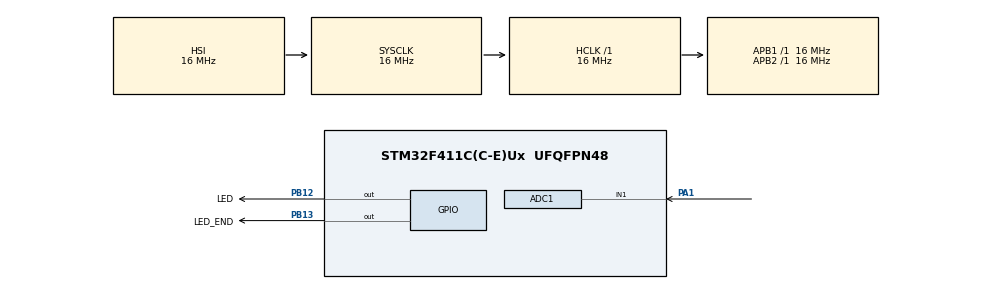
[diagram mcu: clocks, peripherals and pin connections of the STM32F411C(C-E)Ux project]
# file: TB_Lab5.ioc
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ADC1.Channel-2\#ChannelRegularConversion=ADC_CHANNEL_1
ADC1.InjNumberOfConversion=0
ADC1.NbrOfConversionFlag=1
ADC1.Rank-2\#ChannelRegularConversion=1
ADC1.SamplingTime-2\#ChannelRegularConversion=ADC_SAMPLETIME_3CYCLES
ADC1.master=1
Dma.ADC1.0.Direction=DMA_PERIPH_TO_MEMORY
Dma.ADC1.0.FIFOMode=DMA_FIFOMODE_DISABLE
Dma.ADC1.0.Instance=DMA2_Stream0
Dma.ADC1.0.MemDataAlignment=DMA_MDATAALIGN_HALFWORD
Dma.ADC1.0.MemInc=DMA_MINC_ENABLE
Dma.ADC1.0.Mode=DMA_NORMAL
Dma.ADC1.0.PeriphDataAlignment=DMA_PDATAALIGN_HALFWORD
Dma.ADC1.0.PeriphInc=DMA_PINC_DISABLE
Dma.ADC1.0.Priority=DMA_PRIORITY_LOW
Dma.Request0=ADC1
Mcu.Family=STM32F4
Mcu.Name=STM32F411C(C-E)Ux
Mcu.Package=UFQFPN48
NVIC.DMA2_Stream0_IRQn=true\:0\:0\:false\:false\:true\:false\:true\:true
NVIC.PriorityGroup=NVIC_PRIORITYGROUP_4
NVIC.RTC_WKUP_IRQn=true\:0\:0\:false\:false\:true\:true\:true\:true
NVIC.TIM3_IRQn=true\:0\:0\:false\:false\:true\:true\:true\:true
PA0-WKUP.GPIO_Label=WKUP
PA0-WKUP.Mode=SYS_WakeUp0
PA0-WKUP.Signal=SYS_WKUP
PA1.Signal=ADCx_IN1
PB12.GPIO_Label=LED
PB12.Signal=GPIO_Output
PB13.GPIO_Label=LED_END
PB13.Signal=GPIO_Output
ProjectManager.HeapSize=0x200
ProjectManager.StackSize=0x400
ProjectManager.TargetToolchain=STM32CubeIDE
RCC.AHBFreq_Value=16000000
RCC.APB1Freq_Value=16000000
RCC.APB2Freq_Value=16000000
RCC.CortexFreq_Value=16000000
RCC.HSE_VALUE=25000000
RCC.HSI_VALUE=16000000
RCC.LSE_VALUE=32768
RCC.SYSCLKFreq_VALUE=16000000
RCC.VCOOutputFreq_Value=192000000
RTC.WakeUpClock=RTC_WAKEUPCLOCK_CK_SPRE_16BITS
RTC.WakeUpCounter=15
SH.ADCx_IN1.0=ADC1_IN1,IN1
TIM3.Period=5000-1
TIM3.Prescaler=16000-1
VP_RTC_VS_RTC_Activate.Mode=RTC_Enabled
VP_RTC_VS_RTC_WakeUp_intern.Mode=WakeUp
VP_TIM3_VS_ClockSourceINT.Mode=Internal
board=custom

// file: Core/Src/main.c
/* USER CODE BEGIN Header */
/**
 ******************************************************************************
 * @file           : main.c
 * @brief          : Main program body
 ******************************************************************************
 * @attention
 *
 * Copyright (c) 2023 STMicroelectronics.
 * All rights reserved.
 *
 * This software is licensed under terms that can be found in the LICENSE file
 * in the root directory of this software component.
 * If no LICENSE file comes with this software, it is provided AS-IS.
 *
 ******************************************************************************
 */
/* USER CODE END Header */
#include "main.h"

/* USER CODE BEGIN Includes */
#include <stdio.h>
#include <stdint.h>
/* USER CODE END Includes */

/* USER CODE BEGIN PD */
#define NUMBER_OF_SAMPLES 1024
/* USER CODE END PD */

ADC_HandleTypeDef hadc1;
DMA_HandleTypeDef hdma_adc1;

RTC_HandleTypeDef hrtc;

TIM_HandleTypeDef htim3;

/* USER CODE BEGIN PV */
int16_t buff[NUMBER_OF_SAMPLES];
uint32_t adc_sum;
uint32_t current_val;
uint32_t tic_val;
uint32_t tac_val;
uint32_t counter_tim;
uint32_t last_val;
/* USER CODE END PV */

void SystemClock_Config(void);
static void MX_GPIO_Init(void);
static void MX_DMA_Init(void);
static void MX_ADC1_Init(void);
static void MX_RTC_Init(void);
static void MX_TIM3_Init(void);
/* USER CODE BEGIN PFP */
extern void inistialise_monitor_handles(void);
/* USER CODE END PFP */

/* USER CODE BEGIN 0 */

//printf("TIM: %d, BTN: %d\n", counter_tim, counter_btn);
/* USER CODE END 0 */

int main(void)
{

	/* MCU Configuration--------------------------------------------------------*/

	/* Reset of all peripherals, Initializes the Flash interface and the Systick. */
	HAL_Init();

	/* USER CODE BEGIN Init */
	initialise_monitor_handles();
	/* USER CODE END Init */

	/* Configure the system clock */
	SystemClock_Config();

	/* Initialize all configured peripherals */
	MX_GPIO_Init();
	MX_DMA_Init();
	MX_ADC1_Init();
	MX_RTC_Init();
	MX_TIM3_Init();
	/* USER CODE BEGIN 2 */
	HAL_PWR_EnableSleepOnExit();
	HAL_PWR_EnableWakeUpPin(PWR_WAKEUP_PIN1);
	__HAL_TIM_CLEAR_IT(&htim3, TIM_IT_UPDATE);
	__HAL_PWR_CLEAR_FLAG(PWR_FLAG_WU);
	__HAL_RTC_WAKEUPTIMER_CLEAR_FLAG(&hrtc, RTC_FLAG_WUTF);
	HAL_TIM_Base_Start_IT(&htim3);

	uint32_t counter_tim = HAL_RTCEx_BKUPRead(&hrtc, RTC_BKP_DR0);
	uint32_t last_val = HAL_RTCEx_BKUPRead(&hrtc, RTC_BKP_DR2);

	printf("TIM: %lu\n", counter_tim);

	if (counter_tim > 5000) {
		HAL_GPIO_WritePin(LED_END_GPIO_Port, LED_END_Pin, 1);
		HAL_PWR_EnterSTANDBYMode();
	}

	if (HAL_GPIO_ReadPin(WKUP_GPIO_Port, WKUP_Pin) == 1) {
		HAL_GPIO_WritePin(LED_END_GPIO_Port, LED_END_Pin, 1);
		HAL_PWR_EnterSLEEPMode(0, PWR_SLEEPENTRY_WFI);
		HAL_PWR_EnterSTANDBYMode();
	}

	HAL_GPIO_WritePin(LED_END_GPIO_Port, LED_END_Pin, 1);
	HAL_ADC_Start_DMA(&hadc1, &buff, NUMBER_OF_SAMPLES);

	//pritnf("ADC: %lu\n", current_val);

	HAL_RTCEx_BKUPWrite(&hrtc, RTC_BKP_DR2, current_val);
	HAL_RTCEx_BKUPWrite(&hrtc, RTC_BKP_DR0, (counter_tim + 1));
	HAL_PWR_EnterSLEEPMode(0, PWR_SLEEPENTRY_WFI);
	HAL_PWR_EnterSTANDBYMode();
	/* USER CODE END 2 */

	/* Infinite loop */
	while (1)
	{

	}
}

void SystemClock_Config(void)
{
	RCC_OscInitTypeDef RCC_OscInitStruct = {0};
	RCC_ClkInitTypeDef RCC_ClkInitStruct = {0};

	/** Configure the main internal regulator output voltage
	 */
	__HAL_RCC_PWR_CLK_ENABLE();
	__HAL_PWR_VOLTAGESCALING_CONFIG(PWR_REGULATOR_VOLTAGE_SCALE1);

	/** Initializes the RCC Oscillators according to the specified parameters
	 * in the RCC_OscInitTypeDef structure.
	 */
	RCC_OscInitStruct.OscillatorType = RCC_OSCILLATORTYPE_HSI|RCC_OSCILLATORTYPE_LSI;
	RCC_OscInitStruct.HSIState = RCC_HSI_ON;
	RCC_OscInitStruct.HSICalibrationValue = RCC_HSICALIBRATION_DEFAULT;
	RCC_OscInitStruct.LSIState = RCC_LSI_ON;
	RCC_OscInitStruct.PLL.PLLState = RCC_PLL_NONE;
	if (HAL_RCC_OscConfig(&RCC_OscInitStruct) != HAL_OK)
	{
		Error_Handler();
	}

	/** Initializes the CPU, AHB and APB buses clocks
	 */
	RCC_ClkInitStruct.ClockType = RCC_CLOCKTYPE_HCLK|RCC_CLOCKTYPE_SYSCLK
			|RCC_CLOCKTYPE_PCLK1|RCC_CLOCKTYPE_PCLK2;
	RCC_ClkInitStruct.SYSCLKSource = RCC_SYSCLKSOURCE_HSI;
	RCC_ClkInitStruct.AHBCLKDivider = RCC_SYSCLK_DIV1;
	RCC_ClkInitStruct.APB1CLKDivider = RCC_HCLK_DIV1;
	RCC_ClkInitStruct.APB2CLKDivider = RCC_HCLK_DIV1;

	if (HAL_RCC_ClockConfig(&RCC_ClkInitStruct, FLASH_LATENCY_0) != HAL_OK)
	{
		Error_Handler();
	}
}

static void MX_ADC1_Init(void)
{

	ADC_ChannelConfTypeDef sConfig = {0};

	/** Configure the global features of the ADC (Clock, Resolution, Data Alignment and number of conversion)
	 */
	hadc1.Instance = ADC1;
	hadc1.Init.ClockPrescaler = ADC_CLOCK_SYNC_PCLK_DIV2;
	hadc1.Init.Resolution = ADC_RESOLUTION_12B;
	hadc1.Init.ScanConvMode = DISABLE;
	hadc1.Init.ContinuousConvMode = DISABLE;
	hadc1.Init.DiscontinuousConvMode = DISABLE;
	hadc1.Init.ExternalTrigConvEdge = ADC_EXTERNALTRIGCONVEDGE_NONE;
	hadc1.Init.ExternalTrigConv = ADC_SOFTWARE_START;
	hadc1.Init.DataAlign = ADC_DATAALIGN_RIGHT;
	hadc1.Init.NbrOfConversion = 1;
	hadc1.Init.DMAContinuousRequests = DISABLE;
	hadc1.Init.EOCSelection = ADC_EOC_SINGLE_CONV;
	if (HAL_ADC_Init(&hadc1) != HAL_OK)
	{
		Error_Handler();
	}

	/** Configure for the selected ADC regular channel its corresponding rank in the sequencer and its sample time.
	 */
	sConfig.Channel = ADC_CHANNEL_1;
	sConfig.Rank = 1;
	sConfig.SamplingTime = ADC_SAMPLETIME_3CYCLES;
	if (HAL_ADC_ConfigChannel(&hadc1, &sConfig) != HAL_OK)
	{
		Error_Handler();
	}

}

static void MX_RTC_Init(void)
{

	RTC_TimeTypeDef sTime = {0};
	RTC_DateTypeDef sDate = {0};

	/** Initialize RTC Only
	 */
	hrtc.Instance = RTC;
	hrtc.Init.HourFormat = RTC_HOURFORMAT_24;
	hrtc.Init.AsynchPrediv = 127;
	hrtc.Init.SynchPrediv = 255;
	hrtc.Init.OutPut = RTC_OUTPUT_DISABLE;
	hrtc.Init.OutPutPolarity = RTC_OUTPUT_POLARITY_HIGH;
	hrtc.Init.OutPutType = RTC_OUTPUT_TYPE_OPENDRAIN;
	if (HAL_RTC_Init(&hrtc) != HAL_OK)
	{
		Error_Handler();
	}

	/** Initialize RTC and set the Time and Date
	 */
	sTime.Hours = 0x0;
	sTime.Minutes = 0x0;
	sTime.Seconds = 0x0;
	sTime.DayLightSaving = RTC_DAYLIGHTSAVING_NONE;
	sTime.StoreOperation = RTC_STOREOPERATION_RESET;
	if (HAL_RTC_SetTime(&hrtc, &sTime, RTC_FORMAT_BCD) != HAL_OK)
	{
		Error_Handler();
	}
	sDate.WeekDay = RTC_WEEKDAY_MONDAY;
	sDate.Month = RTC_MONTH_JANUARY;
	sDate.Date = 0x1;
	sDate.Year = 0x0;

	if (HAL_RTC_SetDate(&hrtc, &sDate, RTC_FORMAT_BCD) != HAL_OK)
	{
		Error_Handler();
	}

	/** Enable the WakeUp
	 */
	if (HAL_RTCEx_SetWakeUpTimer_IT(&hrtc, 15, RTC_WAKEUPCLOCK_CK_SPRE_16BITS) != HAL_OK)
	{
		Error_Handler();
	}

}

static void MX_TIM3_Init(void)
{

	TIM_ClockConfigTypeDef sClockSourceConfig = {0};
	TIM_MasterConfigTypeDef sMasterConfig = {0};

	htim3.Instance = TIM3;
	htim3.Init.Prescaler = 16000-1;
	htim3.Init.CounterMode = TIM_COUNTERMODE_UP;
	htim3.Init.Period = 5000-1;
	htim3.Init.ClockDivision = TIM_CLOCKDIVISION_DIV1;
	htim3.Init.AutoReloadPreload = TIM_AUTORELOAD_PRELOAD_DISABLE;
	if (HAL_TIM_Base_Init(&htim3) != HAL_OK)
	{
		Error_Handler();
	}
	sClockSourceConfig.ClockSource = TIM_CLOCKSOURCE_INTERNAL;
	if (HAL_TIM_ConfigClockSource(&htim3, &sClockSourceConfig) != HAL_OK)
	{
		Error_Handler();
	}
	sMasterConfig.MasterOutputTrigger = TIM_TRGO_RESET;
	sMasterConfig.MasterSlaveMode = TIM_MASTERSLAVEMODE_DISABLE;
	if (HAL_TIMEx_MasterConfigSynchronization(&htim3, &sMasterConfig) != HAL_OK)
	{
		Error_Handler();
	}

}

static void MX_DMA_Init(void)
{

	/* DMA controller clock enable */
	__HAL_RCC_DMA2_CLK_ENABLE();

	/* DMA interrupt init */
	/* DMA2_Stream0_IRQn interrupt configuration */
	HAL_NVIC_SetPriority(DMA2_Stream0_IRQn, 0, 0);
	HAL_NVIC_EnableIRQ(DMA2_Stream0_IRQn);

}

static void MX_GPIO_Init(void)
{
	GPIO_InitTypeDef GPIO_InitStruct = {0};

	/* GPIO Ports Clock Enable */
	__HAL_RCC_GPIOA_CLK_ENABLE();
	__HAL_RCC_GPIOB_CLK_ENABLE();

	/*Configure GPIO pin Output Level */
	HAL_GPIO_WritePin(GPIOB, LED_Pin|LED_END_Pin, GPIO_PIN_RESET);

	/*Configure GPIO pins : LED_Pin LED_END_Pin */
	GPIO_InitStruct.Pin = LED_Pin|LED_END_Pin;
	GPIO_InitStruct.Mode = GPIO_MODE_OUTPUT_PP;
	GPIO_InitStruct.Pull = GPIO_NOPULL;
	GPIO_InitStruct.Speed = GPIO_SPEED_FREQ_LOW;
	HAL_GPIO_Init(GPIOB, &GPIO_InitStruct);

}

/* USER CODE BEGIN 4 */
void HAL_ADC_ConvHalfCpltCallback (ADC_HandleTypeDef* hadc) {

}
void HAL_ADC_ConvCpltCallback (ADC_HandleTypeDef* hadc) {
	for (uint8_t i; i>NUMBER_OF_SAMPLES ;i++) {
		adc_sum = adc_sum + buff[i];
	}
	current_val = adc_sum / NUMBER_OF_SAMPLES;
}

void HAL_TIM_PeriodElapsedCallback(TIM_HandleTypeDef *htim)
{
	HAL_PWR_DisableSleepOnExit();
}

/* USER CODE END 4 */

void Error_Handler(void)
{
	__disable_irq();
	while (1)
	{
	}
}
